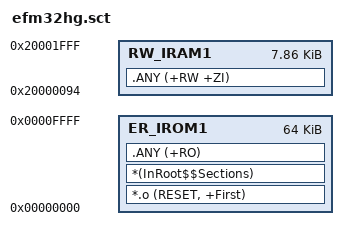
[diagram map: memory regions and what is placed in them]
; *************************************************************
; *** Scatter-Loading Description File generated by uVision ***
; *************************************************************

LR_IROM1 0x00000000 0x00010000  {    ; load region size_region
  ER_IROM1 0x00000000 0x00010000  {  ; load address = execution address
   *.o (RESET, +First)
   *(InRoot$$Sections)
   .ANY (+RO)
  }
  RW_IRAM1 0x20000094 0x00001F6C  {  ; RW data
   .ANY (+RW +ZI)
  }
}

